# PIC32CM1216PL10048 register map
Vendor: Microchip Technology; Series: PIC32CMPL10; File version: 0
CPU: CM0+ r0p0, little endian, no MPU, no FPU, VTOR, 2 interrupt priority bits, 15 interrupts
Registers are 32-bit, read-write, reset 0x0 unless marked. A register's access mark holds for its fields unless they carry their own. Offsets are from the block's base; [hi:lo] are bit positions; lines under a group give offsets from that group; {n}, {i} and the like mark numbered series; 'fields as' and 'values as' point back to an identical list.

## TC0 — Timer/Counter
Base 0x42000C00; register names take the prefix TC_
Same registers: TC1 0x42001000, TC2 0x42001400
0x00 COUNT8 group — 8-bit Counter Mode
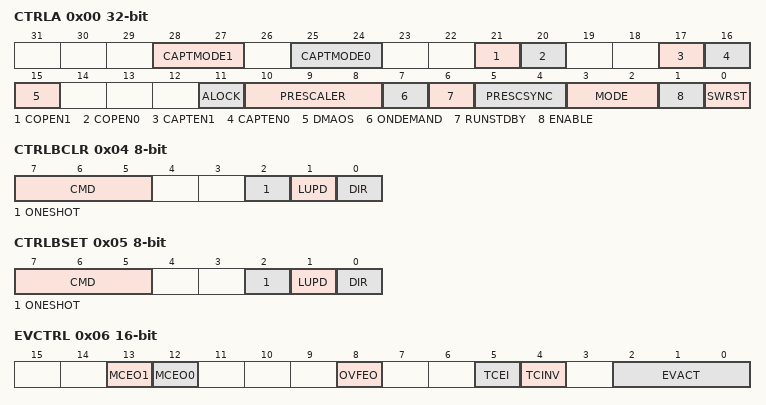
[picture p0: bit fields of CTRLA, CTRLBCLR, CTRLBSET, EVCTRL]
  0x00 CTRLA — Control A
    [28:27] CAPTMODE1 — Capture mode Channel 1
      0=DEFAULT (Default capture); 1=CAPTMIN (Minimum capture); 2=CAPTMAX (Maximum capture)
    [25:24] CAPTMODE0 — Capture mode Channel 0
      values as CAPTMODE1
    [21] COPEN1 — Capture On Pin 1 Enable
    [20] COPEN0 — Capture On Pin 0 Enable
    [17] CAPTEN1 — Capture Channel 1 Enable
    [16] CAPTEN0 — Capture Channel 0 Enable
    [15] DMAOS — DMA One-Shot Trigger Mode
    [11] ALOCK — Auto Lock
    [10:8] PRESCALER
      0=DIV1 (Prescaler: GCLK_TC); 1=DIV2 (Prescaler: GCLK_TC/2); 2=DIV4 (Prescaler: GCLK_TC/4); 3=DIV8 (Prescaler: GCLK_TC/8); 4=DIV16 (Prescaler: GCLK_TC/16); 5=DIV64 (Prescaler: GCLK_TC/64); 6=DIV256 (Prescaler: GCLK_TC/256); 7=DIV1024 (Prescaler: GCLK_TC/1024)
    [7] ONDEMAND — Clock On Demand
    [6] RUNSTDBY — Run in Standby
    [5:4] PRESCSYNC — Prescaler and Counter Synchronization
      0=GCLK (Reload or reset the counter on next generic clock); 1=PRESC (Reload or reset the counter on next prescaler clock); 2=RESYNC (Reload or reset the counter on next generic clock. Reset the prescaler counter.)
    [3:2] MODE — Timer Counter Mode
      0=COUNT16 (Counter in 16-bit mode); 1=COUNT8 (Counter in 8-bit mode); 2=COUNT32 (Counter in 32-bit mode)
    [1] ENABLE
    [0] SWRST — Software Reset
  0x04 CTRLBCLR 8-bit write-1-clears — Control B Clear
    [7:5] CMD — Command
    [2] ONESHOT — One-Shot on Counter
    [1] LUPD — Lock Update
    [0] DIR — Counter Direction
  0x05 CTRLBSET 8-bit write-1-sets — Control B Set
    [7:5] CMD — Command
      0=NONE (No action); 1=RETRIGGER (Force a start, restart or retrigger); 2=STOP (Force a stop); 3=UPDATE (Force update of double buffered registers); 4=READSYNC (Force a read synchronization of COUNT); 5=DMAOS (One-shot DMA trigger)
    [2] ONESHOT — One-Shot on Counter
    [1] LUPD — Lock Update
    [0] DIR — Counter Direction
  0x06 EVCTRL 16-bit — Event Control
    [13] MCEO1 — Match or Capture Channel 1 Event Output Enable
    [12] MCEO0 — Match or Capture Channel 0 Event Output Enable
    [8] OVFEO — Overflow/Underflow Event Output Enable
    [5] TCEI — TC Event Input Enable
    [4] TCINV — TC Inverted Event Input Polarity
    [2:0] EVACT — Event Action
      0=OFF (Event action disabled); 1=RETRIGGER (Start, restart or retrigger TC on event); 2=COUNT (Count on event); 3=START (Start TC on event); 4=STAMP (Time stamp capture); 5=PPW (Period captured in CC0, pulse width in CC1); 6=PWP (Period captured in CC1, pulse width in CC0); 7=PW (Pulse width capture)
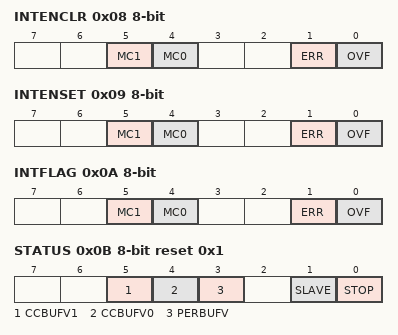
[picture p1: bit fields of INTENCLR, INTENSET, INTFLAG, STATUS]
  0x08 INTENCLR 8-bit write-1-clears — Interrupt Enable Clear
    [5] MC1 — Match or Capture Channel 1 Interrupt Enable
    [4] MC0 — Match or Capture Channel 0 Interrupt Enable
    [1] ERR — Error Interrupt Enable
    [0] OVF — Overflow Interrupt Enable
  0x09 INTENSET 8-bit write-1-sets — Interrupt Enable Set
    fields as COUNT8.INTENCLR
  0x0A INTFLAG 8-bit write-1-clears — Interrupt Flag Status and Clear
    [5] MC1 — Match or Capture Channel 1
    [4] MC0 — Match or Capture Channel 0
    [1] ERR — Error Interrupt Flag
    [0] OVF — Overflow Interrupt Flag
  0x0B STATUS 8-bit reset 0x1
    [5] CCBUFV1 — Channel 1 Compare or Capture Buffer Valid
    [4] CCBUFV0 — Channel 0 Compare or Capture Buffer Valid
    [3] PERBUFV — Period Buffer Valid
    [1] SLAVE — Client Status Flag
    [0] STOP — Stop Status Flag
  0x0C WAVE 8-bit — Waveform Generation Control
    [1:0] WAVEGEN — Waveform Generation Mode
      0=NFRQ (Normal Frequency Generation mode); 1=MFRQ (Match Frequency Generation mode); 2=NPWM (Normal Pulse-Width Modulation mode); 3=MPWM (Match Pulse-Width Modulation mode)
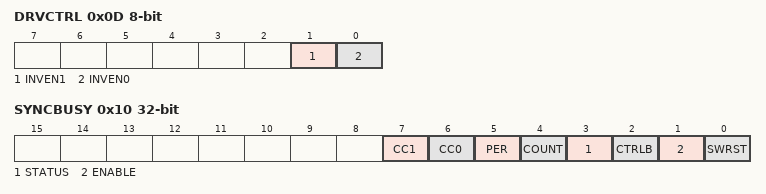
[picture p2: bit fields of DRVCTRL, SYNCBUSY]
  0x0D DRVCTRL 8-bit — Driver Control
    [1] INVEN1 — Waveform Output 1 Invert Enable
    [0] INVEN0 — Waveform Output 0 Invert Enable
  0x0F DBGCTRL 8-bit — Debug Control
    [0] DBGRUN — Run in Debug Mode
  0x10 SYNCBUSY ro — Synchronization Busy
    [7] CC1 — Compare/Capture Channel 1 Synchronization Busy
    [6] CC0 — Compare/Capture Channel 0 Synchronization Busy
    [5] PER — PER Synchronization Busy
    [4] COUNT — COUNT Synchronization Busy
    [3] STATUS — STATUS Synchronization Busy
    [2] CTRLB — CTRLB Synchronization Busy
    [1] ENABLE — ENABLE Synchronization Busy
    [0] SWRST — SWRST Synchronization Busy
  0x14 COUNT 8-bit — COUNT8 Counter
    [7:0] COUNT — Counter Value
  0x1B PER 8-bit reset 0xFF — COUNT8 Period
    [7:0] PER — Period Value
  {0x1C+j} CC[{j}] (j=0..1) 8-bit — COUNT8 Channel # Compare/Capture
    [7:0] CC — Channel Compare/Capture Value
  0x2F PERBUF 8-bit reset 0xFF — COUNT8 Period Buffer
    [7:0] PERBUF — Period Buffer Value
  {0x30+j} CCBUF[{j}] (j=0..1) 8-bit — COUNT8 Channel # Compare Buffer
    [7:0] CCBUF — Channel Compare Buffer Value
0x00 COUNT16 group (alternate view of COUNT8) — 16-bit Counter Mode
  0x00 CTRLA — Control A
    fields as COUNT8.CTRLA
  0x04 CTRLBCLR 8-bit write-1-clears — Control B Clear
    fields as COUNT8.CTRLBCLR
  0x05 CTRLBSET 8-bit write-1-sets — Control B Set
    fields as COUNT8.CTRLBSET
  0x06 EVCTRL 16-bit — Event Control
    fields as COUNT8.EVCTRL
  0x08 INTENCLR 8-bit write-1-clears — Interrupt Enable Clear
    fields as COUNT8.INTENCLR
  0x09 INTENSET 8-bit write-1-sets — Interrupt Enable Set
    fields as COUNT8.INTENCLR
  0x0A INTFLAG 8-bit write-1-clears — Interrupt Flag Status and Clear
    fields as COUNT8.INTFLAG
  0x0B STATUS 8-bit reset 0x1
    fields as COUNT8.STATUS
  0x0C WAVE 8-bit — Waveform Generation Control
    fields as COUNT8.WAVE
  0x0D DRVCTRL 8-bit — Driver Control
    fields as COUNT8.DRVCTRL
  0x0F DBGCTRL 8-bit — Debug Control
    [0] DBGRUN — Run in Debug Mode
  0x10 SYNCBUSY ro — Synchronization Busy
    fields as COUNT8.SYNCBUSY
  0x14 COUNT 16-bit — COUNT16 Counter
    [15:0] COUNT — Counter Value
  {0x1C+2j} CC[{j}] (j=0..1) 16-bit — COUNT16 Channel # Compare/Capture
    [15:0] CC — Channel Compare/Capture Value
  {0x30+2j} CCBUF[{j}] (j=0..1) 16-bit — COUNT16 Channel # Compare Buffer
    [15:0] CCBUF — Channel Compare Buffer Value
0x00 COUNT32 group (alternate view of COUNT8) — 32-bit Counter Mode
  0x00 CTRLA — Control A
    fields as COUNT8.CTRLA
  0x04 CTRLBCLR 8-bit write-1-clears — Control B Clear
    fields as COUNT8.CTRLBCLR
  0x05 CTRLBSET 8-bit write-1-sets — Control B Set
    fields as COUNT8.CTRLBSET
  0x06 EVCTRL 16-bit — Event Control
    fields as COUNT8.EVCTRL
  0x08 INTENCLR 8-bit write-1-clears — Interrupt Enable Clear
    fields as COUNT8.INTENCLR
  0x09 INTENSET 8-bit write-1-sets — Interrupt Enable Set
    fields as COUNT8.INTENCLR
  0x0A INTFLAG 8-bit write-1-clears — Interrupt Flag Status and Clear
    fields as COUNT8.INTFLAG
  0x0B STATUS 8-bit reset 0x1
    fields as COUNT8.STATUS
  0x0C WAVE 8-bit — Waveform Generation Control
    fields as COUNT8.WAVE
  0x0D DRVCTRL 8-bit — Driver Control
    fields as COUNT8.DRVCTRL
  0x0F DBGCTRL 8-bit — Debug Control
    [0] DBGRUN — Run in Debug Mode
  0x10 SYNCBUSY ro — Synchronization Busy
    fields as COUNT8.SYNCBUSY
  0x14 COUNT — COUNT32 Counter
    [31:0] COUNT — Counter Value
  {0x1C+4j} CC[{j}] (j=0..1) — COUNT32 Channel # Compare/Capture
    [31:0] CC — Channel Compare/Capture Value
  {0x30+4j} CCBUF[{j}] (j=0..1) — COUNT32 Channel # Compare Buffer
    [31:0] CCBUF — Channel Compare Buffer Value

## Notices in the file
Copyright (c) 2026 Microchip Technology Inc.
SPDX-License-Identifier: Apache-2.0
Licensed under the Apache License, Version 2.0 (the "License");
you may not use this file except in compliance with the License.
You may obtain a copy of the License at
http://www.apache.org/licenses/LICENSE-2.0
Unless required by applicable law or agreed to in writing, software
distributed under the License is distributed on an "AS IS" BASIS,
WITHOUT WARRANTIES OR CONDITIONS OF ANY KIND, either express or implied.
See the License for the specific language governing permissions and
limitations under the License.
